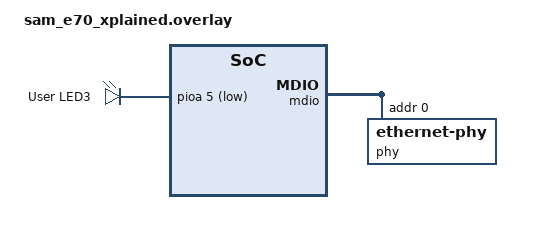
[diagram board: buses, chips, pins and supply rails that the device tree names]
/*
 * Copyright (c) 2021 Nordic Semiconductor ASA
 * SPDX-License-Identifier: Apache-2.0
 */

/* This devicetree overlay file will be automatically picked by the Zephyr
 * build system when building the sample for the sam_E70 and sam_E70(B) board. It shows
 * how the example-application can be built on sample boards already provided
 * by Zephyr.
 */

/ {
	aliases{
		led3 = &yellow_led;
	};

	chosen {
		
	};

	leds{
		compatible = "gpio-leds";

		yellow_led: led_3 {
			gpios = <&pioa 5 GPIO_ACTIVE_LOW>;
			label = "User LED3";
		};
	};
};

&mdio {
	status = "okay";

	pinctrl-0 = <&mdio_default>;
	pinctrl-names = "default";

	//CHANGING DEFAULT ETHERNET PHY TO REG 1
	phy: ethernet-phy@0 {
		compatible = "ethernet-phy";
		status = "okay";
		reg = <0>;
		//reg=<1> for LAN9370
		//fixed-link = "100BASE-T Full-Duplex";
	};

	/*
	phy: ethernet-phy@0 {
		compatible = "ethernet-phy";
		status = "okay";
		reg = <0>;
		reg = <1>;
		reg = <2>;
		no-reset = "false";
	};
	 */

};
